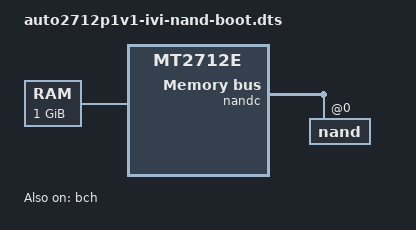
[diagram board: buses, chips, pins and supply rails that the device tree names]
// SPDX-License-Identifier: GPL-2.0
/*
 * Copyright (c) 2019 MediaTek Inc.
 */

/dts-v1/;
#include "mt2712e.dtsi"
#include "auto2712p1v1-common.dtsi"

/ {
	chosen {
		bootargs = "console=ttyS0,921600n1 ubi.mtd=4 rootfstype=ubifs root=ubi0_0 ubi.mtd=5 rootwait earlycon=uart8250,mmio32,0x11002000";
	};

	memory@40000000 {
		device_type = "memory";
		reg = <0 0x40000000 0 0x40000000>;
	};
};

&bch {
	status = "okay";
};

&it6151_5c {
	resolution-index = <2>;
};

&nandc {
	pinctrl-names = "default";
	pinctrl-0 = <&nand_pins_default>;
	status = "okay";
	nand@0 {
		reg = <0>;
		nand-on-flash-bbt;
		nand-ecc-mode = "hw";
	};
};
